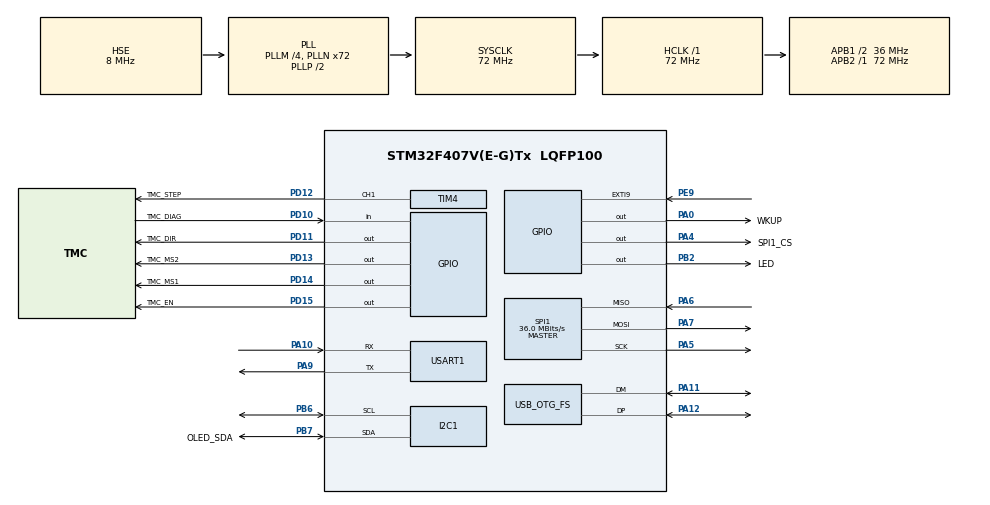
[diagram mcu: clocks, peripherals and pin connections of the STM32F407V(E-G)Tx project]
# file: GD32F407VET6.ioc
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Mcu.Family=STM32F4
Mcu.Name=STM32F407V(E-G)Tx
Mcu.Package=LQFP100
NVIC.PriorityGroup=NVIC_PRIORITYGROUP_4
NVIC.TIM2_IRQn=true\:15\:0\:false\:false\:true\:false\:false\:true\:true
NVIC.TimeBase=TIM2_IRQn
NVIC.TimeBaseIP=TIM2
NVIC.USART1_IRQn=true\:0\:0\:false\:false\:true\:false\:true\:true\:true
PA0-WKUP.GPIO_Label=WKUP
PA0-WKUP.Signal=GPIO_Output
PA10.Mode=Asynchronous
PA10.Signal=USART1_RX
PA11.Mode=Host_Only
PA11.Signal=USB_OTG_FS_DM
PA12.Mode=Host_Only
PA12.Signal=USB_OTG_FS_DP
PA13.Mode=Serial_Wire
PA13.Signal=SYS_JTMS-SWDIO
PA14.Mode=Serial_Wire
PA14.Signal=SYS_JTCK-SWCLK
PA4.GPIO_Label=SPI1_CS
PA4.Signal=GPIO_Output
PA5.Mode=Full_Duplex_Master
PA5.Signal=SPI1_SCK
PA6.Mode=Full_Duplex_Master
PA6.Signal=SPI1_MISO
PA7.Mode=Full_Duplex_Master
PA7.Signal=SPI1_MOSI
PA9.Mode=Asynchronous
PA9.Signal=USART1_TX
PB2.GPIO_Label=LED
PB2.GPIO_PuPd=GPIO_PULLDOWN
PB2.Signal=GPIO_Output
PB6.Mode=I2C
PB6.Signal=I2C1_SCL
PB7.GPIO_Label=OLED_SDA
PB7.Mode=I2C
PB7.Signal=I2C1_SDA
PC12.Signal=SDIO_CK
PD10.GPIO_Label=TMC_DIAG
PD10.Signal=GPIO_Input
PD11.GPIO_Label=TMC_DIR
PD11.Signal=GPIO_Output
PD12.GPIO_Label=TMC_STEP
PD12.Signal=S_TIM4_CH1
PD13.GPIO_Label=TMC_MS2
PD13.Signal=GPIO_Output
PD14.GPIO_Label=TMC_MS1
PD14.Signal=GPIO_Output
PD15.GPIO_Label=TMC_EN
PD15.Signal=GPIO_Output
PE9.Signal=GPXTI9
PH0-OSC_IN.Mode=HSE-External-Oscillator
PH0-OSC_IN.Signal=RCC_OSC_IN
PH1-OSC_OUT.Mode=HSE-External-Oscillator
PH1-OSC_OUT.Signal=RCC_OSC_OUT
ProjectManager.HeapSize=0x200
ProjectManager.StackSize=0x400
ProjectManager.TargetToolchain=MDK-ARM V5.32
RCC.48MHZClocksFreq_Value=48000000
RCC.AHBFreq_Value=72000000
RCC.APB1CLKDivider=RCC_HCLK_DIV2
RCC.APB1Freq_Value=36000000
RCC.APB1TimFreq_Value=72000000
RCC.APB2Freq_Value=72000000
RCC.APB2TimFreq_Value=72000000
RCC.CortexFreq_Value=72000000
RCC.HCLKFreq_Value=72000000
RCC.HSE_VALUE=8000000
RCC.HSI_VALUE=16000000
RCC.LSE_VALUE=32768
RCC.PLLM=4
RCC.PLLN=72
RCC.PLLQ=3
RCC.SYSCLKFreq_VALUE=72000000
RCC.SYSCLKSource=RCC_SYSCLKSOURCE_PLLCLK
RCC.VCOOutputFreq_Value=144000000
RealThread.RT-Thread.3.1.5.RTOSJjkernel=true
SH.S_TIM4_CH1.0=TIM4_CH1,PWM Generation1 CH1
SPI1.CalculateBaudRate=36.0 MBits/s
SPI1.Direction=SPI_DIRECTION_2LINES
SPI1.Mode=SPI_MODE_MASTER
SPI1.VirtualType=VM_MASTER
TIM1.Prescaler=167
TIM4.AutoReloadPreload=TIM_AUTORELOAD_PRELOAD_ENABLE
TIM4.Channel-PWM\ Generation1\ CH1=TIM_CHANNEL_1
TIM4.Period=4095
TIM4.Prescaler=7
TIM4.Pulse-PWM\ Generation1\ CH1=0
USART1.VirtualMode=VM_ASYNC
USB_OTG_FS.VirtualMode=Host_Only
USB_OTG_FS.phy_itface=HCD_PHY_EMBEDDED
VP_RealThread.RT-Thread_VS_RTOSJjkernel_3.1.5_3.1.5.Mode=RTOSJjkernel
VP_SYS_VS_tim2.Mode=TIM2
VP_TIM1_VS_ClockSourceINT.Mode=Internal
VP_TIM4_VS_ClockSourceINT.Mode=Internal
board=custom

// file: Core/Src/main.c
/* USER CODE BEGIN Header */
/**
 ******************************************************************************
 * @file main.c
 * @brief          : Main program body
 ******************************************************************************
 * @attention
 *
 * Copyright (c) 2024 STMicroelectronics.
 * All rights reserved.
 *
 * This software is licensed under terms that can be found in the LICENSE file
 * in the root directory of this software component.
 * If no LICENSE file comes with this software, it is provided AS-IS.
 *
 ******************************************************************************
 */
/* USER CODE END Header */
#include "main.h"
#include "i2c.h"
#include "spi.h"
#include "tim.h"
#include "usart.h"
#include "usb_otg.h"
#include "gpio.h"

/* USER CODE BEGIN Includes */
#include <rtthread.h>

#include "delay.h"
#include "app.h"
/* USER CODE END Includes */

void SystemClock_Config(void);

int main(void)
{

  /* MCU Configuration--------------------------------------------------------*/

  /* Reset of all peripherals, Initializes the Flash interface and the Systick. */
  HAL_Init();

  /* Configure the system clock */
  SystemClock_Config();

  /* Initialize all configured peripherals */
  MX_GPIO_Init();
  MX_I2C1_Init();
  MX_TIM1_Init();
  MX_USART1_UART_Init();
  MX_SPI1_Init();
  MX_USB_OTG_FS_HCD_Init();
  MX_TIM4_Init();
  /* USER CODE BEGIN 2 */
  delay_init(SystemCoreClock / 1000000); /* 延时初始化 */
  app_init();
  /* USER CODE END 2 */

  /* Infinite loop */
  while (1)
  {

    /* USER CODE BEGIN 3 */
    rt_thread_mdelay(1000);
  }
  /* USER CODE END 3 */
}

void SystemClock_Config(void)
{
  RCC_OscInitTypeDef RCC_OscInitStruct = {0};
  RCC_ClkInitTypeDef RCC_ClkInitStruct = {0};

  /** Configure the main internal regulator output voltage
  */
  __HAL_RCC_PWR_CLK_ENABLE();
  __HAL_PWR_VOLTAGESCALING_CONFIG(PWR_REGULATOR_VOLTAGE_SCALE1);

  /** Initializes the RCC Oscillators according to the specified parameters
  * in the RCC_OscInitTypeDef structure.
  */
  RCC_OscInitStruct.OscillatorType = RCC_OSCILLATORTYPE_HSE;
  RCC_OscInitStruct.HSEState = RCC_HSE_ON;
  RCC_OscInitStruct.PLL.PLLState = RCC_PLL_ON;
  RCC_OscInitStruct.PLL.PLLSource = RCC_PLLSOURCE_HSE;
  RCC_OscInitStruct.PLL.PLLM = 4;
  RCC_OscInitStruct.PLL.PLLN = 72;
  RCC_OscInitStruct.PLL.PLLP = RCC_PLLP_DIV2;
  RCC_OscInitStruct.PLL.PLLQ = 3;
  if (HAL_RCC_OscConfig(&RCC_OscInitStruct) != HAL_OK)
  {
    Error_Handler();
  }

  /** Initializes the CPU, AHB and APB buses clocks
  */
  RCC_ClkInitStruct.ClockType = RCC_CLOCKTYPE_HCLK|RCC_CLOCKTYPE_SYSCLK
                              |RCC_CLOCKTYPE_PCLK1|RCC_CLOCKTYPE_PCLK2;
  RCC_ClkInitStruct.SYSCLKSource = RCC_SYSCLKSOURCE_PLLCLK;
  RCC_ClkInitStruct.AHBCLKDivider = RCC_SYSCLK_DIV1;
  RCC_ClkInitStruct.APB1CLKDivider = RCC_HCLK_DIV2;
  RCC_ClkInitStruct.APB2CLKDivider = RCC_HCLK_DIV1;

  if (HAL_RCC_ClockConfig(&RCC_ClkInitStruct, FLASH_LATENCY_2) != HAL_OK)
  {
    Error_Handler();
  }
}

void HAL_TIM_PeriodElapsedCallback(TIM_HandleTypeDef *htim)
{
  if (htim->Instance == TIM2) {
    HAL_IncTick();
  }
}

void Error_Handler(void)
{
  __disable_irq();
  while (1)
  {
  }
}
